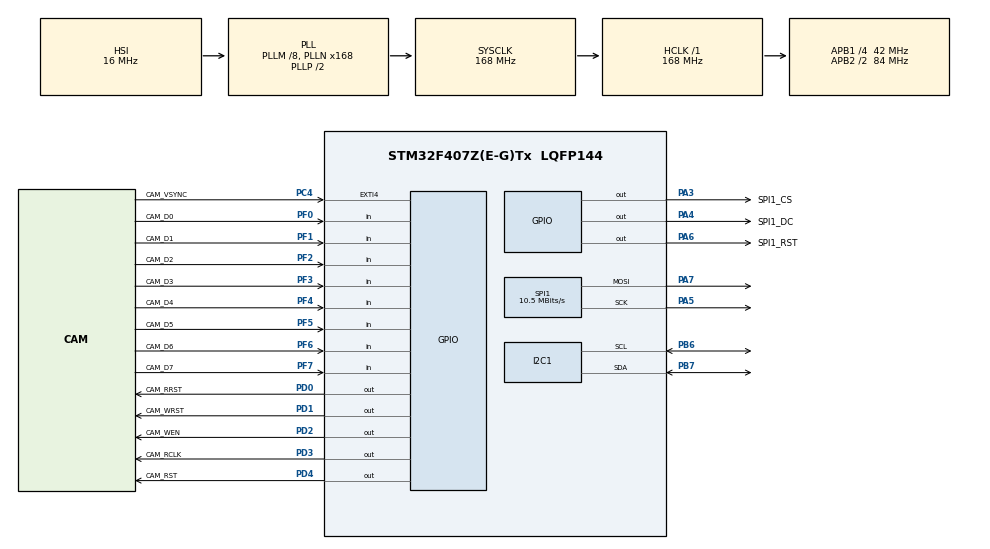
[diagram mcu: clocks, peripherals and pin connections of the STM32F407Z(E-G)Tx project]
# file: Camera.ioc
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Mcu.Family=STM32F4
Mcu.Name=STM32F407Z(E-G)Tx
Mcu.Package=LQFP144
NVIC.EXTI4_IRQn=true\:0\:0\:false\:false\:true\:true\:true\:true
NVIC.PriorityGroup=NVIC_PRIORITYGROUP_4
PA13.Mode=Serial_Wire
PA13.Signal=SYS_JTMS-SWDIO
PA14.Mode=Serial_Wire
PA14.Signal=SYS_JTCK-SWCLK
PA3.GPIO_Label=SPI1_CS
PA3.Signal=GPIO_Output
PA4.GPIO_Label=SPI1_DC
PA4.Signal=GPIO_Output
PA5.GPIO_Speed=GPIO_SPEED_FREQ_HIGH
PA5.Mode=TX_Only_Simplex_Unidirect_Master
PA5.Signal=SPI1_SCK
PA6.GPIO_Label=SPI1_RST
PA6.Signal=GPIO_Output
PA7.GPIO_Speed=GPIO_SPEED_FREQ_HIGH
PA7.Mode=TX_Only_Simplex_Unidirect_Master
PA7.Signal=SPI1_MOSI
PB6.GPIO_Pu=GPIO_PULLUP
PB6.Mode=I2C
PB6.Signal=I2C1_SCL
PB7.GPIO_Pu=GPIO_PULLUP
PB7.Mode=I2C
PB7.Signal=I2C1_SDA
PC14-OSC32_IN.Mode=LSE-External-Oscillator
PC14-OSC32_IN.Signal=RCC_OSC32_IN
PC15-OSC32_OUT.Mode=LSE-External-Oscillator
PC15-OSC32_OUT.Signal=RCC_OSC32_OUT
PC4.GPIO_Label=CAM_VSYNC
PC4.GPIO_ModeDefaultEXTI=GPIO_MODE_IT_FALLING
PC4.GPIO_PuPd=GPIO_PULLUP
PC4.Signal=GPXTI4
PD0.GPIO_Label=CAM_RRST
PD0.GPIO_Speed=GPIO_SPEED_FREQ_VERY_HIGH
PD0.Signal=GPIO_Output
PD1.GPIO_Label=CAM_WRST
PD1.GPIO_Speed=GPIO_SPEED_FREQ_VERY_HIGH
PD1.Signal=GPIO_Output
PD2.GPIO_Label=CAM_WEN
PD2.GPIO_Speed=GPIO_SPEED_FREQ_VERY_HIGH
PD2.Signal=GPIO_Output
PD3.GPIO_Label=CAM_RCLK
PD3.GPIO_Speed=GPIO_SPEED_FREQ_VERY_HIGH
PD3.Signal=GPIO_Output
PD4.GPIO_Label=CAM_RST
PD4.GPIO_Speed=GPIO_SPEED_FREQ_VERY_HIGH
PD4.Signal=GPIO_Output
PF0.GPIO_Label=CAM_D0
PF0.Signal=GPIO_Input
PF1.GPIO_Label=CAM_D1
PF1.Signal=GPIO_Input
PF2.GPIO_Label=CAM_D2
PF2.Signal=GPIO_Input
PF3.GPIO_Label=CAM_D3
PF3.Signal=GPIO_Input
PF4.GPIO_Label=CAM_D4
PF4.Signal=GPIO_Input
PF5.GPIO_Label=CAM_D5
PF5.Signal=GPIO_Input
PF6.GPIO_Label=CAM_D6
PF6.Signal=GPIO_Input
PF7.GPIO_Label=CAM_D7
PF7.Signal=GPIO_Input
PH0-OSC_IN.Mode=HSE-External-Oscillator
PH0-OSC_IN.Signal=RCC_OSC_IN
PH1-OSC_OUT.Mode=HSE-External-Oscillator
PH1-OSC_OUT.Signal=RCC_OSC_OUT
ProjectManager.HeapSize=0x200
ProjectManager.StackSize=0x400
ProjectManager.TargetToolchain=MDK-ARM V5.32
RCC.48MHZClocksFreq_Value=84000000
RCC.AHBFreq_Value=168000000
RCC.APB1CLKDivider=RCC_HCLK_DIV4
RCC.APB1Freq_Value=42000000
RCC.APB1TimFreq_Value=84000000
RCC.APB2CLKDivider=RCC_HCLK_DIV2
RCC.APB2Freq_Value=84000000
RCC.APB2TimFreq_Value=168000000
RCC.CortexFreq_Value=168000000
RCC.HCLKFreq_Value=168000000
RCC.HSE_VALUE=25000000
RCC.HSI_VALUE=16000000
RCC.PLLM=8
RCC.PLLN=168
RCC.RCC_RTC_Clock_Source=RCC_RTCCLKSOURCE_LSE
RCC.RCC_RTC_Clock_SourceVirtual=RCC_RTCCLKSOURCE_LSE
RCC.SYSCLKFreq_VALUE=168000000
RCC.SYSCLKSource=RCC_SYSCLKSOURCE_PLLCLK
RCC.VCOOutputFreq_Value=336000000
RTC.Date=6
RTC.Hours=15
RTC.Minutes=30
RTC.Month=RTC_MONTH_JULY
RTC.Year=20
SPI1.BaudRatePrescaler=SPI_BAUDRATEPRESCALER_8
SPI1.CalculateBaudRate=10.5 MBits/s
SPI1.Direction=SPI_DIRECTION_2LINES
SPI1.Mode=SPI_MODE_MASTER
SPI1.VirtualType=VM_MASTER
VP_RTC_VS_RTC_Activate.Mode=RTC_Enabled
VP_RTC_VS_RTC_Calendar.Mode=RTC_Calendar
VP_RTC_VS_RTC_WakeUp_intern.Mode=WakeUp
board=custom

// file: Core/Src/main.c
/* USER CODE BEGIN Header */
/**
 ******************************************************************************
 * @file           : main.c
 * @brief          : Main program body
 ******************************************************************************
 * @attention
 *
 * Copyright (c) 2024 STMicroelectronics.
 * All rights reserved.
 *
 * This software is licensed under terms that can be found in the LICENSE file
 * in the root directory of this software component.
 * If no LICENSE file comes with this software, it is provided AS-IS.
 *
 ******************************************************************************
 */
/* USER CODE END Header */
#include "main.h"
#include "i2c.h"
#include "rtc.h"
#include "spi.h"
#include "gpio.h"

/* USER CODE BEGIN Includes */
#include "oled.h"
#include "st7735.h"
#include "ov7670.h"
/* USER CODE END Includes */

void SystemClock_Config(void);

int main(void)
{

	/* MCU Configuration--------------------------------------------------------*/

	/* Reset of all peripherals, Initializes the Flash interface and the Systick. */
	HAL_Init();

	/* Configure the system clock */
	SystemClock_Config();

	/* Initialize all configured peripherals */
	MX_GPIO_Init();
	MX_RTC_Init();
	MX_SPI1_Init();
	MX_I2C1_Init();
	/* USER CODE BEGIN 2 */
	ST7735_Init();
	OLED_Init();
	ov7670_init();
	OLED_test();
	ST7735_FillScreen(ST7735_BLACK);
	ST7735_ShowNum(50, 50, 1, 1, ST7735_WHITE);
	ST7735_WriteAll();

	/* USER CODE END 2 */

	/* Infinite loop */
	while (1)
	{

		/* USER CODE BEGIN 3 */
		if (take_photo_flag == 0)
		{
			camera_refresh();
			ST7735_WriteAll();
			take_photo_flag = 1;
		}

	}
	/* USER CODE END 3 */
}

void SystemClock_Config(void)
{
	RCC_OscInitTypeDef RCC_OscInitStruct = {0};
	RCC_ClkInitTypeDef RCC_ClkInitStruct = {0};

	/** Configure the main internal regulator output voltage
	 */
	__HAL_RCC_PWR_CLK_ENABLE();
	__HAL_PWR_VOLTAGESCALING_CONFIG(PWR_REGULATOR_VOLTAGE_SCALE1);

	/** Initializes the RCC Oscillators according to the specified parameters
	 * in the RCC_OscInitTypeDef structure.
	 */
	RCC_OscInitStruct.OscillatorType = RCC_OSCILLATORTYPE_HSI | RCC_OSCILLATORTYPE_LSE;
	RCC_OscInitStruct.LSEState = RCC_LSE_ON;
	RCC_OscInitStruct.HSIState = RCC_HSI_ON;
	RCC_OscInitStruct.HSICalibrationValue = RCC_HSICALIBRATION_DEFAULT;
	RCC_OscInitStruct.PLL.PLLState = RCC_PLL_ON;
	RCC_OscInitStruct.PLL.PLLSource = RCC_PLLSOURCE_HSI;
	RCC_OscInitStruct.PLL.PLLM = 8;
	RCC_OscInitStruct.PLL.PLLN = 168;
	RCC_OscInitStruct.PLL.PLLP = RCC_PLLP_DIV2;
	RCC_OscInitStruct.PLL.PLLQ = 4;
	if (HAL_RCC_OscConfig(&RCC_OscInitStruct) != HAL_OK)
	{
		Error_Handler();
	}

	/** Initializes the CPU, AHB and APB buses clocks
	 */
	RCC_ClkInitStruct.ClockType = RCC_CLOCKTYPE_HCLK | RCC_CLOCKTYPE_SYSCLK | RCC_CLOCKTYPE_PCLK1 | RCC_CLOCKTYPE_PCLK2;
	RCC_ClkInitStruct.SYSCLKSource = RCC_SYSCLKSOURCE_PLLCLK;
	RCC_ClkInitStruct.AHBCLKDivider = RCC_SYSCLK_DIV1;
	RCC_ClkInitStruct.APB1CLKDivider = RCC_HCLK_DIV4;
	RCC_ClkInitStruct.APB2CLKDivider = RCC_HCLK_DIV2;

	if (HAL_RCC_ClockConfig(&RCC_ClkInitStruct, FLASH_LATENCY_5) != HAL_OK)
	{
		Error_Handler();
	}
}

void Error_Handler(void)
{
	__disable_irq();
	while (1)
	{
	}
}
